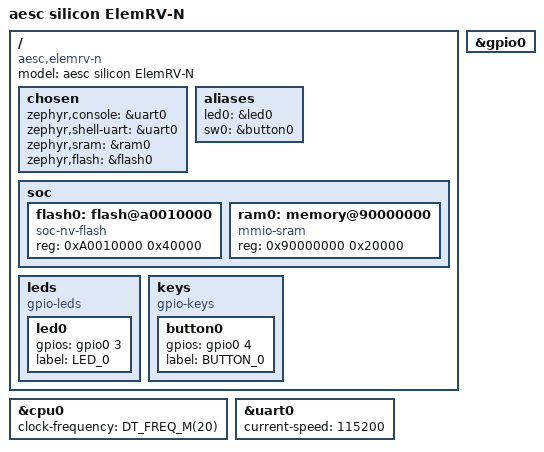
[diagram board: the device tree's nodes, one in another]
/*
 * Copyright (C) 2025 aesc silicon
 * Author: Daniel Schultz <d.schultz@phytec.de>
 *
 * SPDX-License-Identifier: Apache-2.0
 */

/dts-v1/;

#include <elements/elemrv-n.dtsi>

/ {
	model = "aesc silicon ElemRV-N";
	compatible = "aesc,elemrv-n";

	chosen {
		zephyr,console = &uart0;
		zephyr,shell-uart = &uart0;
		zephyr,sram = &ram0;
		zephyr,flash = &flash0;
	};

	aliases {
		led0 = &led0;
		sw0 = &button0;
	};

	soc {
		flash0: flash@a0010000 {
			compatible = "soc-nv-flash";
			reg = <0xA0010000 0x40000>;
		};

		ram0: memory@90000000 {
			device_type = "memory";
			compatible = "mmio-sram";
			reg = <0x90000000 0x20000>;
		};
	};

	leds: leds {
		compatible = "gpio-leds";
		led0: led0 {
			gpios = <&gpio0 3 GPIO_ACTIVE_HIGH>;
			label = "LED_0";
		};
	};

	keys: keys {
		compatible = "gpio-keys";
		button0: button0 {
			gpios = <&gpio0 4 GPIO_ACTIVE_HIGH>;
			label = "BUTTON_0";
		};
	};
};

&cpu0 {
	clock-frequency = <DT_FREQ_M(20)>;
};

&uart0 {
	current-speed = <115200>;
	status = "okay";
};

&gpio0 {
	status = "okay";
};
